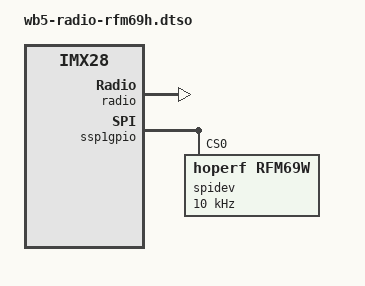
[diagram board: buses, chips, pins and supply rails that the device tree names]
/dts-v1/;
/plugin/;

/*
 * Standard definitions for RFM69H for WB5
 */

/ {
    compatible = "contactless,imx28-wirenboard58","contactless,imx28-wirenboard55", "contactless,imx28-wirenboard52";

    fragment-radio-rfm69h-description {
        target-path = "/wirenboard";

        __overlay__ {
            radio {
                model = "rfm69h";
                frequencies-mhz = <433>;
            };
        };
    };

    /* Enable SPI for RFM module and add spidev node */
    fragment-wb5-rfm69h-spi {
        target = <&ssp1gpio>;

        __overlay__ {
            status = "okay";
            #address-cells = <1>;
            #size-cells = <0>;

            spidev@0 {
			    compatible = "hoperf,rfm69w";
			    spi-max-frequency = <10000>;
			    reg = <0>;
		    };
        };
    };

    fragment-wb5-rfm69h-status {
        target-path = "/wirenboard";

        __overlay__ {
            radio {
                status = "okay";
            };
        };
    };
};
